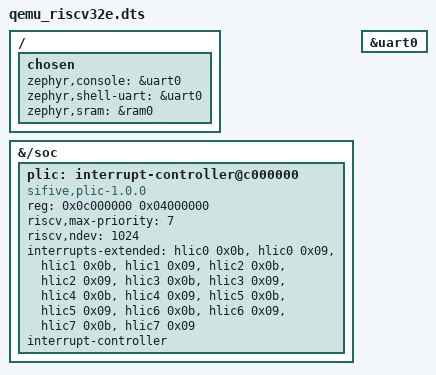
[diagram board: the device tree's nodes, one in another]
/*
 * Copyright (c) 2022 Carlo Caione <ccaione@baylibre.com>
 *
 * SPDX-License-Identifier: Apache-2.0
 *
 */

/dts-v1/;

#include <qemu/virt-riscv32e.dtsi>

/ {
	chosen {
		zephyr,console = &uart0;
		zephyr,shell-uart = &uart0;
		zephyr,sram = &ram0;
	};
};

&{/soc} {
	plic: interrupt-controller@c000000 {
		compatible = "sifive,plic-1.0.0";
		reg = <0x0c000000 0x04000000>;
		riscv,max-priority = <7>;
		riscv,ndev = <1024>;
		interrupts-extended = <&hlic0 0x0b &hlic0 0x09
				       &hlic1 0x0b &hlic1 0x09
				       &hlic2 0x0b &hlic2 0x09
				       &hlic3 0x0b &hlic3 0x09
				       &hlic4 0x0b &hlic4 0x09
				       &hlic5 0x0b &hlic5 0x09
				       &hlic6 0x0b &hlic6 0x09
				       &hlic7 0x0b &hlic7 0x09>;
		interrupt-controller;
		#address-cells = <0x00>;
		#interrupt-cells = <0x02>;
	};
};

&uart0 {
	status = "okay";
};
